# KM1M7CF15 register map
Vendor: Nuvoton Technology Corporation Japan; Series: KM1M7CF; File version: 1.0.3
CPU: CM7 r1p2, little endian, MPU, FPU, double-precision FPU, I-cache, D-cache, ITCM, DTCM, 4 interrupt priority bits
Registers are 32-bit, read-write, no defined reset value unless marked. A register's access mark holds for its fields unless they carry their own. Offsets are from the block's base; [hi:lo] are bit positions.

## MAP — RAM-ECC
Base 0x40005000
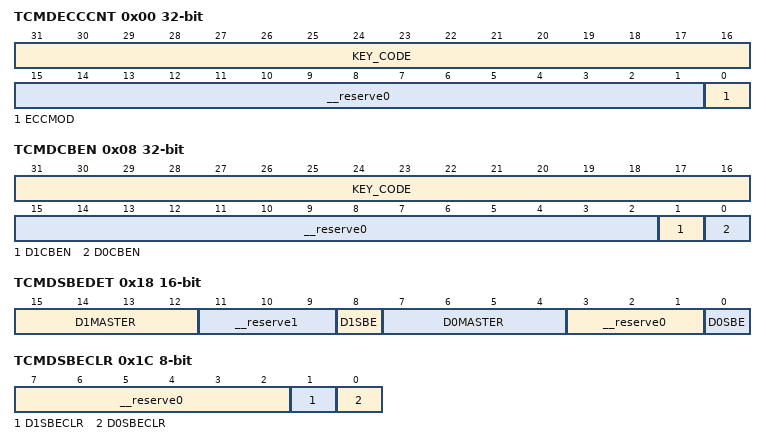
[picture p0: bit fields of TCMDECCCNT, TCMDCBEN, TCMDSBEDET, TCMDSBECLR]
0x00 TCMDECCCNT access per field — D0TCM/D1TCM ECC Control Register
  [31:16] KEY_CODE rw — When TCMDECCCNT.KEY_CODE is set to "0x3CA5", TCMDECCCNT is updated.
  [15:1] __reserve0 ro — "0" is always read out.
  [0] ECCMOD rw — ECC enable [D0TCM, D1TCM]
0x08 TCMDCBEN access per field — D0TCM/D1TCM Check Bit Control Register
  [31:16] KEY_CODE rw — When TCMDCBEN.KEY_CODE is set to "0x3CA5", TCMDCBEN is updated.
  [15:2] __reserve0 ro — "0" is always read out.
  [1] D1CBEN rw — Check bit write enable [D1TCM]
  [0] D0CBEN rw — Check bit write enable [D0TCM]
0x10 TCMD0SBEA ro — D0TCM 1-bit Error Address Register
  [31:0] SBEADD — The 1-bit error address [D0TCM]
0x14 TCMD1SBEA ro — D1TCM 1-bit Error Address Register
  [31:0] SBEADD — The 1-bit error address [D1TCM]
0x18 TCMDSBEDET 16-bit ro — D0TCM/D1TCM 1-bit Error Detection Register
  [15:12] D1MASTER — Memory access at 1-bit error [D1TCM]
  [11:9] __reserve1 — "0" is always read out.
  [8] D1SBE — 1-bit error detection bit [D1TCM]
  [7:4] D0MASTER — Memory access at 1-bit error [D0TCM]
  [3:1] __reserve0 — "0" is always read out.
  [0] D0SBE — 1-bit error detection bit [D0TCM]
0x1C TCMDSBECLR 8-bit access per field — D0TCM/D1TCM 1-bit Error Detection Clear Register
  [7:2] __reserve0 ro — "0" is always read out.
  [1] D1SBECLR rw — Clear the 1-bit error detection [D1TCM]
  [0] D0SBECLR rw — Clear the 1-bit error detection [D0TCM]
0x20 TCMD0MBEA ro — D0TCM 2-bit Error Address Register
  [31:0] MBEADD — The 2-bit error or hardware error address [D0TCM]
0x24 TCMD1MBEA ro — D1TCM 2-bit Error Address Register
  [31:0] MBEADD — The 2-bit error or hardware error address [D1TCM]
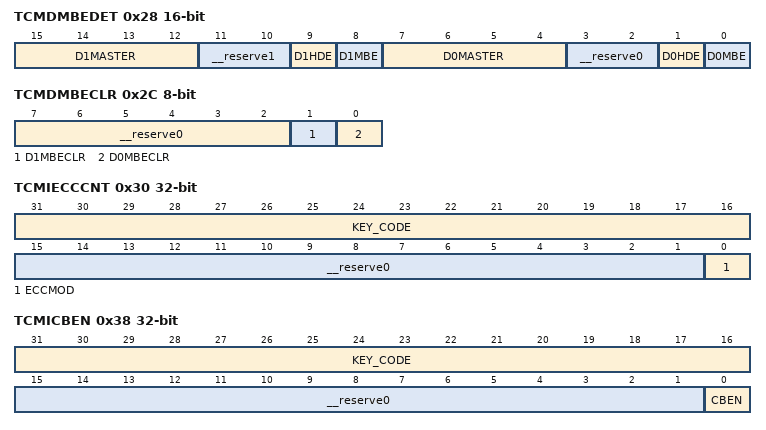
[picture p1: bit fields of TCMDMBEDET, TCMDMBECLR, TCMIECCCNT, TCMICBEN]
0x28 TCMDMBEDET 16-bit ro — D0TCM/D1TCM 2-bit Error Detection Register
  [15:12] D1MASTER — Memory access at 2-bit error or hardware error [D1TCM]
  [11:10] __reserve1 — "0" is always read out.
  [9] D1HDE — Hardware error detection bit [D1TCM]
  [8] D1MBE — 2-bit error detection bit [D1TCM]
  [7:4] D0MASTER — Memory access at 2-bit error or hardware error [D0TCM]
  [3:2] __reserve0 — "0" is always read out.
  [1] D0HDE — Hardware error detection bit [D0TCM]
  [0] D0MBE — 2-bit error detection bit [D0TCM]
0x2C TCMDMBECLR 8-bit access per field — D0TCM/D1TCM 2-bit Error Detection Clear Register
  [7:2] __reserve0 ro — "0" is always read out.
  [1] D1MBECLR rw — Clear the 2-bit error and hardware error detection [D1TCM]
  [0] D0MBECLR rw — Clear the 2-bit error and hardware error detection [D0TCM]
0x30 TCMIECCCNT access per field — ITCM ECC Control Register
  [31:16] KEY_CODE rw — When TCMIECCCNT.KEY_CODE is set to "0xA5C3", TCMIECCCNT is updated.
  [15:1] __reserve0 ro — "0" is always read out.
  [0] ECCMOD rw — ECC enable [ITCM]
0x38 TCMICBEN access per field — ITCM Check Bit Control Register
  [31:16] KEY_CODE rw — When TCMICBEN.KEY_CODE is set to "0xA5C3", TCMICBEN is updated.
  [15:1] __reserve0 ro — "0" is always read out.
  [0] CBEN rw — Check bit read/write enable [ITCM]
0x40 TCMISBEA ro — ITCM 1-bit Error Address Register
  [31:0] SBEADD — The 1bit error address [ITCM]
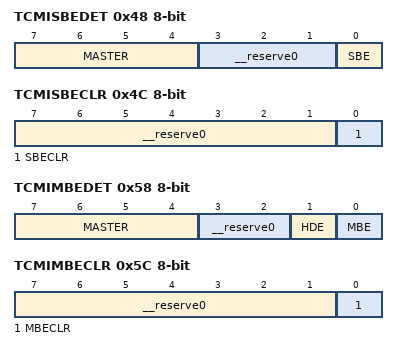
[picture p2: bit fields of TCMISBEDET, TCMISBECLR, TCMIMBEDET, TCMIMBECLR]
0x48 TCMISBEDET 8-bit ro — ITCM 1-bit Error Detection Register
  [7:4] MASTER — Memory access at 1-bit error [ITCM]
  [3:1] __reserve0 — "0" is always read out.
  [0] SBE — 1-bit error detection bit [ITCM]
0x4C TCMISBECLR 8-bit access per field — ITCM 1-bit Error Detection Clear Register
  [7:1] __reserve0 ro — "0" is always read out.
  [0] SBECLR rw — Clear the 1-bit error detection [ITCM]
0x50 TCMIMBEA ro — ITCM 2-bit Error Address Register
  [31:0] MBEADD — The 2-bit error or hardware error address [ITCM]
0x58 TCMIMBEDET 8-bit ro — ITCM 2-bit Error Detection Register
  [7:4] MASTER — Memory access at 2-bit error or hardware error [ITCM]
  [3:2] __reserve0 — "0" is always read out.
  [1] HDE — Hardware error detection bit [ITCM]
  [0] MBE — 2-bit error detection bit [ITCM]
0x5C TCMIMBECLR 8-bit access per field — ITCM 2-bit Error Detection Clear Register
  [7:1] __reserve0 ro — "0" is always read out.
  [0] MBECLR rw — Clear the 2-bit error and hardware error detection [ITCM]
